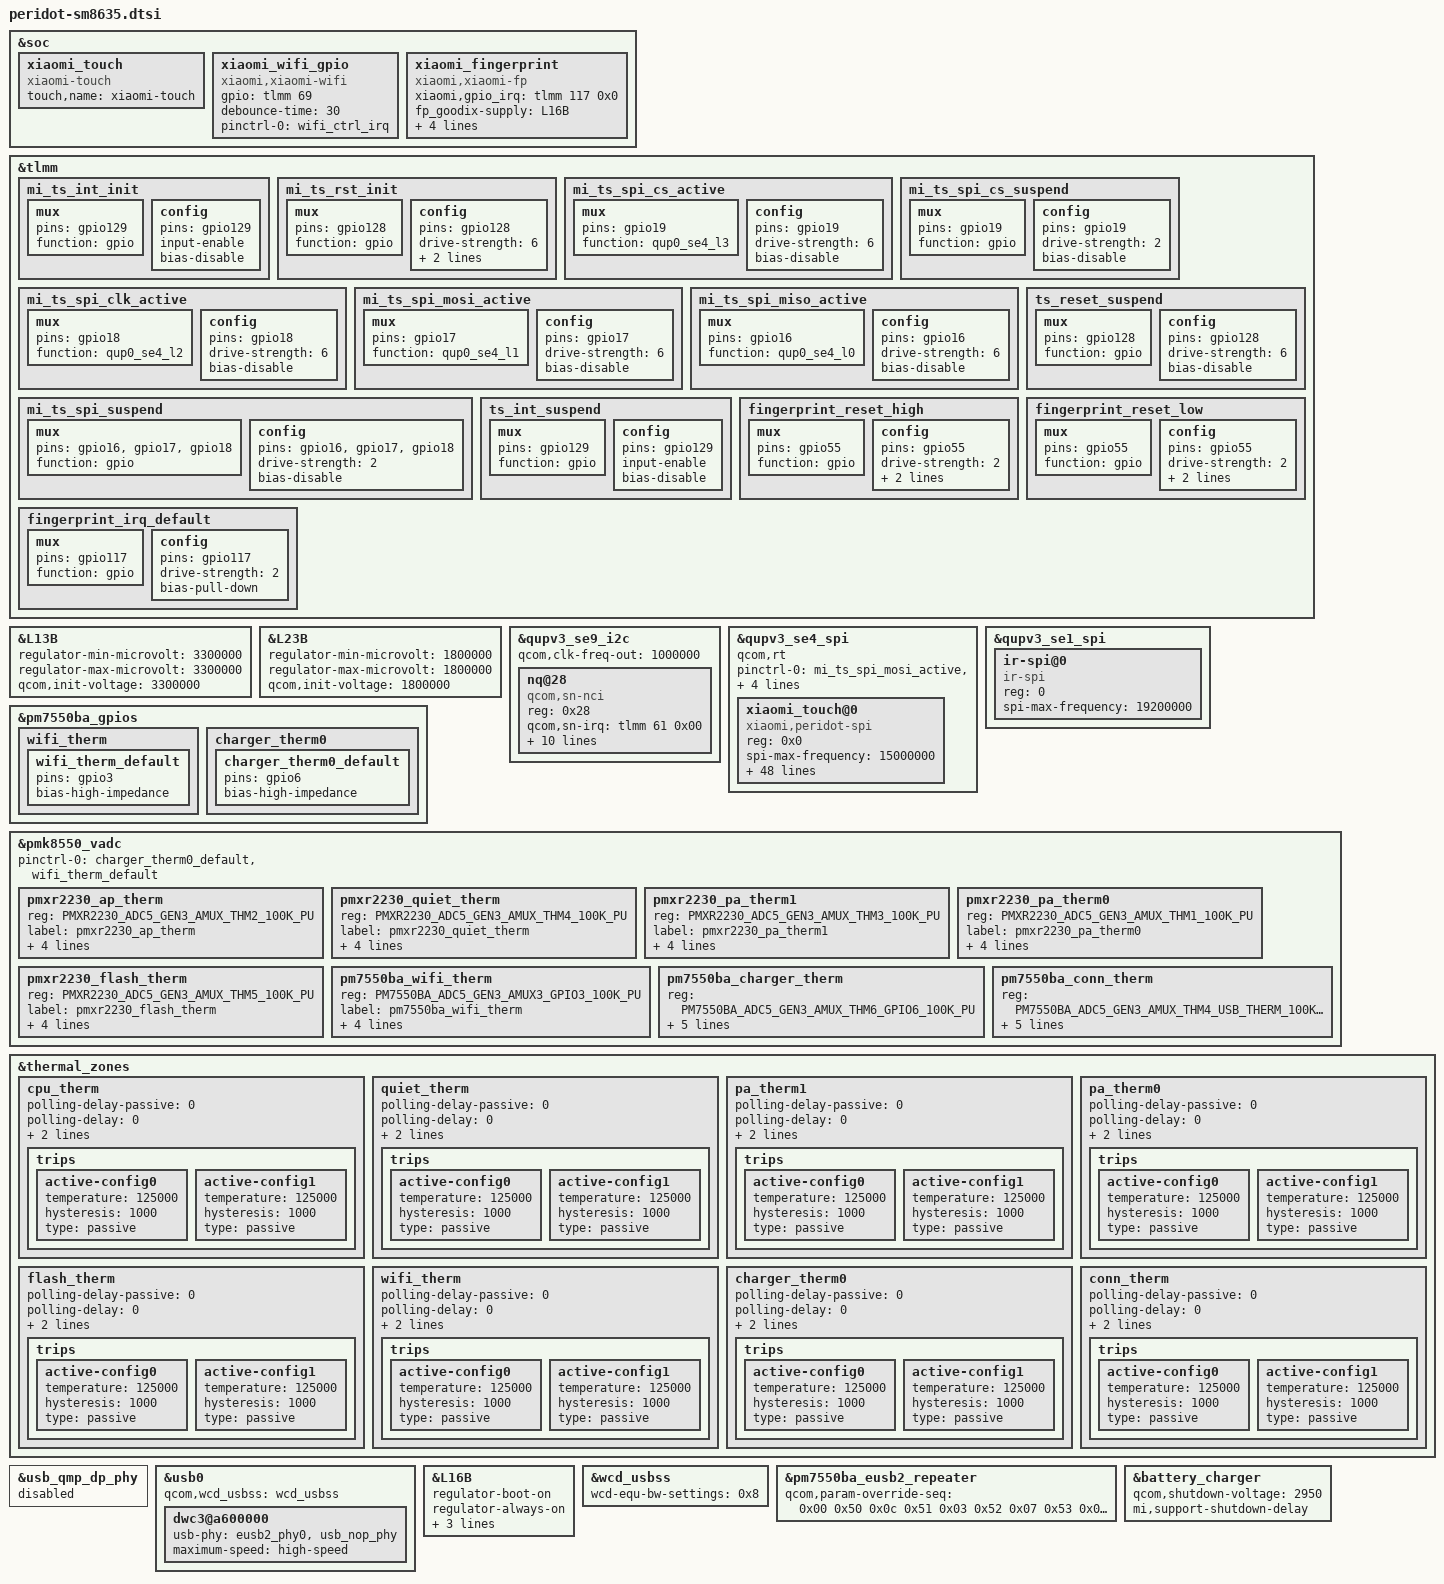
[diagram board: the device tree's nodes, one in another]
/*
  this file is for attribution only of peridot
  And public attribution of xiaomi platforms(like N16T and so and)
*/
#define PERIDOT_REGULATOR_OCP
#include "peridot-pinctrl.dtsi"
#include "xiaomi-sm8635-common.dtsi"
#include "cliffs-pm7550ba.dtsi"

&soc {
	xiaomi_touch {
		compatible = "xiaomi-touch";
		status = "ok";
		touch,name = "xiaomi-touch";
	};

	xiaomi_wifi_gpio {
		compatible = "xiaomi,xiaomi-wifi";
		gpio = <&tlmm 69 0x00>;
		debounce-time = <30>;
		pinctrl-names = "default";
		pinctrl-0 = <&wifi_ctrl_irq>;
		status = "ok";
	};
};

&tlmm {
	mi_ts_int_init: mi_ts_int_init {
		mux {
			pins = "gpio129";
			function = "gpio";
		};

		config {
			pins = "gpio129";
			input-enable;
			bias-disable;
		};
	};
	mi_ts_rst_init: mi_ts_rst_init {
		mux {
			pins = "gpio128";
			function = "gpio";
		};

		config {
			pins = "gpio128";
			drive-strength = <6>;
			bias-disable;
			output-low;
		};
	};

	mi_ts_spi_cs_active: mi_ts_spi_cs_active {
		mux {
			pins = "gpio19";
			function = "qup0_se4_l3";
		};

		config {
			pins = "gpio19";
			drive-strength = <6>;
			bias-disable;
		};
	};

    mi_ts_spi_cs_suspend: mi_ts_spi_cs_suspend {
		mux {
			pins = "gpio19";
			function = "gpio";
		};

		config {
			pins = "gpio19";
			drive-strength = <2>;
			bias-disable;
		};
	};

	mi_ts_spi_clk_active: mi_ts_spi_clk_active {
		mux {
			pins = "gpio18";
			function = "qup0_se4_l2";
		};
		config {
			pins = "gpio18";
			drive-strength = <6>;
			bias-disable;
		};
	};

	mi_ts_spi_mosi_active: mi_ts_spi_mosi_active {
		mux {
			pins = "gpio17";
			function = "qup0_se4_l1";
		};
		config {
			pins = "gpio17";
			drive-strength = <6>;
			bias-disable;
		};
	};


	mi_ts_spi_miso_active: mi_ts_spi_miso_active {
		mux {
			pins = "gpio16";
			function = "qup0_se4_l0";
		};
		config {
			pins = "gpio16";
			drive-strength = <6>;
			bias-disable;
		};
	};


	mi_ts_spi_suspend: mi_ts_spi_suspend {
		mux {
			pins = "gpio16", "gpio17", "gpio18";
			function = "gpio";
		};

		config {
			pins = "gpio16", "gpio17", "gpio18";
			drive-strength = <2>;
			bias-disable;
		};
	};

	ts_reset_suspend: ts_reset_suspend {
		mux {
			pins = "gpio128";
			function = "gpio";
		};

		config {
			pins = "gpio128";
			drive-strength = <6>;
			bias-disable;
		};
	};

	ts_int_suspend: ts_int_suspend {
		mux {
			pins = "gpio129";
			function = "gpio";
		};

		config {
			pins = "gpio129";
			input-enable;
			bias-disable;
		};
	};

};

&L13B {
	regulator-min-microvolt = <3300000>;
	regulator-max-microvolt = <3300000>;
	qcom,init-voltage = <3300000>;
};

&L23B {
	regulator-min-microvolt = <1800000>;
	regulator-max-microvolt = <1800000>;
	qcom,init-voltage = <1800000>;
};

&qupv3_se9_i2c {
	status = "ok";
	qcom,clk-freq-out = <1000000>;
	#address-cells = <1>;
	#size-cells = <0>;
	nq@28 {
		compatible = "qcom,sn-nci";
		reg = <0x28>;
		qcom,sn-irq = <&tlmm 61 0x00>;
		qcom,sn-ven = <&tlmm 114 0x00>;
		qcom,sn-clkreq = <&tlmm 115 0x00>;
		qcom,sn-szone = "enable";
		qcom,sn-vdd-1p8-supply = <&L5B>;
		qcom,sn-vdd-1p8-voltage = <1200000 1200000>;
		qcom,sn-vdd-1p8-current = <157000>;
		interrupt-parent = <&tlmm>;
		interrupts = <61 0>;
		interrupt-names = "nfc_irq";
		pinctrl-names = "nfc_active", "nfc_suspend";
		pinctrl-0 = <&nfc_int_active &nfc_enable_active>;
		pinctrl-1 = <&nfc_int_suspend &nfc_enable_suspend>;
	};
};

&qupv3_se4_spi {
	status = "ok";
	qcom,rt;
	pinctrl-0 = <&mi_ts_spi_mosi_active>, <&mi_ts_spi_miso_active>,
				<&mi_ts_spi_clk_active>, <&mi_ts_spi_cs_active>;
	pinctrl-1 = <&mi_ts_spi_suspend>, <&mi_ts_spi_cs_suspend>;
	xiaomi_touch@0 {
		status = "ok";
		compatible = "xiaomi,peridot-spi", "focaltech,n16t-3683g-spi";
		reg = <0x0>;
		spi-max-frequency = <15000000>;
		interrupt-parent = <&tlmm>;
		interrupts = <129 0x2008>;
		pinctrl-names = "pmx_ts_active", "pmx_ts_suspend";
		pinctrl-0 = <&mi_ts_int_init &mi_ts_rst_init>;
		pinctrl-1 = <&ts_int_suspend &ts_reset_suspend>;

		vdd-supply = <&L23B>;
		avdd-supply = <&L13B>;

		/* parameters for 1st supplier goodix */
		goodix,avdd-name = "avdd";
		goodix,iovdd-name = "vdd";
		goodix,irq-gpio = <&tlmm 129 0x2008>;
		goodix,reset-gpio = <&tlmm 128 0x00>;
		goodix,irq-flags = <2>;
		goodix,panel-max-x = <19520>;
		goodix,panel-max-y = <43392>;
		goodix,panel-max-w = <255>;
		goodix,panel-max-p = <4096>;
		goodix,super-resolution-factor = <16>;
		goodix,firmware-name = "goodix_firmware_peridot_csot";
		goodix,config-name = "goodix_cfg_group_peridot_csot";
		goodix,touch-expert-array = <2 3 2 2
					     4 3 3 2
					     3 3 4 2>;

		/* parameters for 2nd supplier focaltech */
		focaltech,avdd-name = "avdd";
		focaltech,iovdd-name = "vdd";
		focaltech,irq-gpio = <&tlmm 129 0x2008>;
		focaltech,reset-gpio = <&tlmm 128 0x00>;
		focaltech,max-touch-number = <10>;
		focaltech,super-resolution-factors = <16>;
		focaltech,display-coords =  <0 0 19520 43392>;
		focaltech,touch-range-array = <1 5 10 15 20>;
		focaltech,touch-def-array = <3 3 3 3>;
		focaltech,touch-expert-array = <10 10 10 10
										20 20 15 10
										20 20 20 10>;
		focaltech,support-fod = <1>;
		focaltech,fod-lx = <504>;
		focaltech,fod-ly = <2332>;
		focaltech,fod-x-size = <210>;
		focaltech,fod-y-size = <210>;

		/* parameters for xiaomi_touch */
		mi_tp,game-mode-array =
				<1 0 0 0 0>;  /* MAX MIN DEF SET GET	*/
		mi_tp,active-mode-array =
				<1 0 0 0 0>;  /* MAX MIN DEF SET GET	*/
		mi_tp,tolerance-array =
				<4 0 2 2 2>;  /* MAX MIN DEF SET GET	*/
		mi_tp,up-threshold-array =
				<4 0 3 3 3>;  /* MAX MIN DEF SET GET	*/
		mi_tp,aim-sensitivity-array =
				<4 0 2 2 2>;  /* MAX MIN DEF SET GET	*/
		mi_tp,tap-stability-array =
				<4 0 2 2 2>;  /* MAX MIN DEF SET GET	*/
		mi_tp,edge-filter-array =
				<3 0 2 2 2>;  /* MAX MIN DEF SET GET	*/
		mi_tp,panel-orien-array =
				<3 0 0 0 0>;  /* MAX MIN DEF SET GET	*/
		mi_tp,report-rate-array =
				<3 0 0 0 0>;  /* MAX MIN DEF SET GET	*/
		mi_tp,expert-mode-array =
				<3 1 1 1 1>;  /* MAX MIN DEF SET GET	*/
	};
};

&qupv3_se1_spi {
	status = "ok";
	ir-spi@0 {
		compatible = "ir-spi";
		reg = <0>;
		spi-max-frequency = <19200000>;
		status = "ok";
	};
};

&pm7550ba_gpios{
	wifi_therm {
		wifi_therm_default:wifi_therm_default {
		pins = "gpio3";
		bias-high-impedance;
		};
	};
};

&pm7550ba_gpios{
	charger_therm0 {
		charger_therm0_default:charger_therm0_default {
		pins = "gpio6";
		bias-high-impedance;
		};
	};
};

&pmk8550_vadc {
	pinctrl-names = "default";
	pinctrl-0 = <&charger_therm0_default>, <&wifi_therm_default>;

	pmxr2230_ap_therm {
		reg = <PMXR2230_ADC5_GEN3_AMUX_THM2_100K_PU>;
		label = "pmxr2230_ap_therm";
		qcom,ratiometric;
		qcom,hw-settle-time = <200>;
		qcom,pre-scaling = <1 1>;
		qcom,adc-tm-type = <1>;
	};

	pmxr2230_quiet_therm {
		reg = <PMXR2230_ADC5_GEN3_AMUX_THM4_100K_PU>;
		label = "pmxr2230_quiet_therm";
		qcom,ratiometric;
		qcom,hw-settle-time = <200>;
		qcom,pre-scaling = <1 1>;
		qcom,adc-tm-type = <1>;
	};

	pmxr2230_pa_therm1 {
		reg = <PMXR2230_ADC5_GEN3_AMUX_THM3_100K_PU>;
		label = "pmxr2230_pa_therm1";
		qcom,ratiometric;
		qcom,hw-settle-time = <200>;
		qcom,pre-scaling = <1 1>;
		qcom,adc-tm-type = <1>;
	};

	pmxr2230_pa_therm0 {
		reg = <PMXR2230_ADC5_GEN3_AMUX_THM1_100K_PU>;
		label = "pmxr2230_pa_therm0";
		qcom,ratiometric;
		qcom,hw-settle-time = <200>;
		qcom,pre-scaling = <1 1>;
		qcom,adc-tm-type = <1>;
	};

	pmxr2230_flash_therm {
		reg = <PMXR2230_ADC5_GEN3_AMUX_THM5_100K_PU>;
		label = "pmxr2230_flash_therm";
		qcom,ratiometric;
		qcom,hw-settle-time = <200>;
		qcom,pre-scaling = <1 1>;
		qcom,adc-tm-type = <1>;
	};

	pm7550ba_wifi_therm {
		reg = <PM7550BA_ADC5_GEN3_AMUX3_GPIO3_100K_PU>;
		label = "pm7550ba_wifi_therm";
		qcom,ratiometric;
		qcom,hw-settle-time = <200>;
		qcom,pre-scaling = <1 1>;
		qcom,adc-tm-type = <1>;
	};

	pm7550ba_charger_therm {
		reg = <PM7550BA_ADC5_GEN3_AMUX_THM6_GPIO6_100K_PU>;
		label = "pm7550ba_charger_therm";
		qcom,ratiometric;
		qcom,hw-settle-time = <200>;
		qcom,pre-scaling = <1 1>;
		qcom,adc-tm-type = <1>;
	};

	pm7550ba_conn_therm {
		reg = <PM7550BA_ADC5_GEN3_AMUX_THM4_USB_THERM_100K_PU>;
		label = "pm7550ba_conn_therm";
		qcom,ratiometric;
		qcom,hw-settle-time = <200>;
		qcom,pre-scaling = <1 1>;
		qcom,adc-tm-type = <1>;
	};
};

&thermal_zones {
	cpu_therm {
		polling-delay-passive = <0>;
		polling-delay = <0>;
		thermal-sensors = <&pmk8550_vadc PMXR2230_ADC5_GEN3_AMUX_THM2_100K_PU>;
		trips {
			active-config0 {
				temperature = <125000>;
				hysteresis = <1000>;
				type = "passive";
			};

			active-config1 {
				temperature = <125000>;
				hysteresis = <1000>;
				type = "passive";
			};
		};
	};

	quiet_therm {
		polling-delay-passive = <0>;
		polling-delay = <0>;
		thermal-sensors = <&pmk8550_vadc PMXR2230_ADC5_GEN3_AMUX_THM4_100K_PU>;
		trips {
			active-config0 {
				temperature = <125000>;
				hysteresis = <1000>;
				type = "passive";
			};

			active-config1 {
				temperature = <125000>;
				hysteresis = <1000>;
				type = "passive";
			};
		};
	};

	pa_therm1 {
		polling-delay-passive = <0>;
		polling-delay = <0>;
		thermal-sensors = <&pmk8550_vadc PMXR2230_ADC5_GEN3_AMUX_THM3_100K_PU>;
		trips {
			active-config0 {
				temperature = <125000>;
				hysteresis = <1000>;
				type = "passive";
			};

			active-config1 {
				temperature = <125000>;
				hysteresis = <1000>;
				type = "passive";
			};
		};
	};

	pa_therm0 {
		polling-delay-passive = <0>;
		polling-delay = <0>;
		thermal-sensors = <&pmk8550_vadc PMXR2230_ADC5_GEN3_AMUX_THM1_100K_PU>;
		trips {
			active-config0 {
				temperature = <125000>;
				hysteresis = <1000>;
				type = "passive";
			};

			active-config1 {
				temperature = <125000>;
				hysteresis = <1000>;
				type = "passive";
			};
		};
	};

	flash_therm {
		polling-delay-passive = <0>;
		polling-delay = <0>;
		thermal-sensors = <&pmk8550_vadc PMXR2230_ADC5_GEN3_AMUX_THM5_100K_PU>;
		trips {
			active-config0 {
				temperature = <125000>;
				hysteresis = <1000>;
				type = "passive";
			};

			active-config1 {
				temperature = <125000>;
				hysteresis = <1000>;
				type = "passive";
			};
		};
	};

	wifi_therm {
		polling-delay-passive = <0>;
		polling-delay = <0>;
		thermal-sensors = <&pmk8550_vadc PM7550BA_ADC5_GEN3_AMUX3_GPIO3_100K_PU>;
		trips {
			active-config0 {
				temperature = <125000>;
				hysteresis = <1000>;
				type = "passive";
			};

			active-config1 {
				temperature = <125000>;
				hysteresis = <1000>;
				type = "passive";
			};
		};
	};

	charger_therm0 {
		polling-delay-passive = <0>;
		polling-delay = <0>;
		thermal-sensors = <&pmk8550_vadc PM7550BA_ADC5_GEN3_AMUX_THM6_GPIO6_100K_PU>;
		trips {
			active-config0 {
				temperature = <125000>;
				hysteresis = <1000>;
				type = "passive";
			};

			active-config1 {
				temperature = <125000>;
				hysteresis = <1000>;
				type = "passive";
			};
		};
	};
	conn_therm {
		polling-delay-passive = <0>;
		polling-delay = <0>;
		thermal-sensors = <&pmk8550_vadc PM7550BA_ADC5_GEN3_AMUX_THM4_USB_THERM_100K_PU>;
		trips {
			active-config0 {
				temperature = <125000>;
				hysteresis = <1000>;
				type = "passive";
			};

			active-config1 {
				temperature = <125000>;
				hysteresis = <1000>;
				type = "passive";
			};
		};
	};
};

&usb_qmp_dp_phy {
	status = "disabled";
};

&usb0 {
	dwc3@a600000 {
		usb-phy = <&eusb2_phy0>, <&usb_nop_phy>;
		maximum-speed = "high-speed";
 	};
};

&soc {
        xiaomi_fingerprint {
                compatible = "xiaomi,xiaomi-fp";
                xiaomi,gpio_irq = <&tlmm 117 0x0>;
                fp_goodix-supply = <&L16B>;
                netlink-event = <25>;
                pinctrl-names = "reset_high", "reset_low","irq_default";
                pinctrl-0 = <&fingerprint_reset_high>;
                pinctrl-1 = <&fingerprint_reset_low>;
                pinctrl-2 = <&fingerprint_irq_default>;
                status = "ok";
        };
};

&L16B {
	regulator-boot-on;
	regulator-always-on;
	regulator-min-microvolt = <3200000>;
	regulator-max-microvolt = <3200000>;
	qcom,init-voltage = <3200000>;
};

&tlmm {
        /* FP_RESET_HIGH, state device active*/
        fingerprint_reset_high: fingerprint_reset_high {
                mux {
                        pins = "gpio55";
                        function = "gpio";
                };
                config {
                        pins = "gpio55";
                        drive-strength = <2>;
                        bias-disable;
                        output-high;
                };
        };
        /* FP_RESET_LOW */
        fingerprint_reset_low: fingerprint_reset_low {
                mux {
                        pins = "gpio55";
                        function = "gpio";
                };
                config {
                        pins = "gpio55";
                        drive-strength = <2>;
                        bias-disable;
                        output-low;
                };
        };
        /* FP_INT_N */
        fingerprint_irq_default: fingerprint_irq_default {
                mux {
                        pins = "gpio117";
                        function = "gpio";
                };
                config {
                        pins = "gpio117";
                        drive-strength = <2>;
                        bias-pull-down;
                };
        };
};

&usb0 {
        qcom,wcd_usbss = <&wcd_usbss>;
};
&wcd_usbss {
        wcd-equ-bw-settings = <0x8>;
};

&pm7550ba_eusb2_repeater {
        qcom,param-override-seq =
                <0x00 0x50
                0x0c 0x51
                0x03 0x52
                0x07 0x53
                0x02 0x54
                0x03 0x55
                0x00 0x56
                0x04 0x57
                0x02 0x58
                0x00 0x59
                0x03 0x5a
                0x02 0x5b
                0x00 0x5c>;
};
&battery_charger {
	qcom,shutdown-voltage = <2950>;
	mi,support-shutdown-delay;
};
